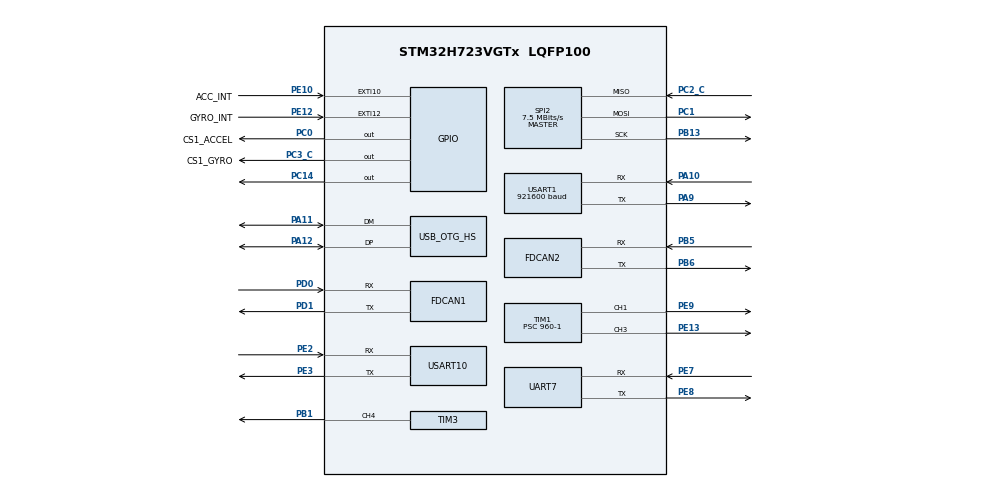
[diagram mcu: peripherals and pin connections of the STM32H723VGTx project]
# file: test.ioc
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Dma.Request0=USART1_RX
Dma.USART1_RX.0.Direction=DMA_PERIPH_TO_MEMORY
Dma.USART1_RX.0.EventEnable=DISABLE
Dma.USART1_RX.0.FIFOMode=DMA_FIFOMODE_DISABLE
Dma.USART1_RX.0.Instance=DMA1_Stream0
Dma.USART1_RX.0.MemDataAlignment=DMA_MDATAALIGN_BYTE
Dma.USART1_RX.0.MemInc=DMA_MINC_ENABLE
Dma.USART1_RX.0.Mode=DMA_NORMAL
Dma.USART1_RX.0.PeriphDataAlignment=DMA_PDATAALIGN_BYTE
Dma.USART1_RX.0.PeriphInc=DMA_PINC_DISABLE
Dma.USART1_RX.0.Polarity=HAL_DMAMUX_REQ_GEN_RISING
Dma.USART1_RX.0.Priority=DMA_PRIORITY_LOW
Dma.USART1_RX.0.RequestNumber=1
Dma.USART1_RX.0.SignalID=NONE
Dma.USART1_RX.0.SyncEnable=DISABLE
Dma.USART1_RX.0.SyncPolarity=HAL_DMAMUX_SYNC_NO_EVENT
Dma.USART1_RX.0.SyncRequestNumber=1
Dma.USART1_RX.0.SyncSignalID=NONE
FDCAN1.AutoRetransmission=DISABLE
FDCAN1.CalculateBaudRateNominal=999999
FDCAN1.CalculateTimeBitNominal=1000
FDCAN1.CalculateTimeQuantumNominal=16.666666666666668
FDCAN1.DataPrescaler=5
FDCAN1.DataSyncJumpWidth=6
FDCAN1.DataTimeSeg1=17
FDCAN1.DataTimeSeg2=6
FDCAN1.ExtFiltersNbr=4
FDCAN1.NominalPrescaler=2
FDCAN1.NominalSyncJumpWidth=15
FDCAN1.NominalTimeSeg1=44
FDCAN1.NominalTimeSeg2=15
FDCAN1.ProtocolException=DISABLE
FDCAN1.RxBuffersNbr=8
FDCAN1.RxFifo0ElmtsNbr=8
FDCAN1.RxFifo1ElmtsNbr=8
FDCAN1.StdFiltersNbr=4
FDCAN1.TxBuffersNbr=8
FDCAN1.TxEventsNbr=8
FDCAN1.TxFifoQueueElmtsNbr=8
FDCAN2.CalculateBaudRateNominal=800000
FDCAN2.CalculateTimeBitNominal=1250
FDCAN2.CalculateTimeQuantumNominal=16.666666666666668
FDCAN2.DataPrescaler=5
FDCAN2.DataSyncJumpWidth=6
FDCAN2.DataTimeSeg1=23
FDCAN2.DataTimeSeg2=6
FDCAN2.ExtFiltersNbr=4
FDCAN2.MessageRAMOffset=853
FDCAN2.NominalPrescaler=2
FDCAN2.NominalSyncJumpWidth=15
FDCAN2.NominalTimeSeg1=59
FDCAN2.NominalTimeSeg2=15
FDCAN2.ProtocolException=ENABLE
FDCAN2.RxBuffersNbr=8
FDCAN2.RxFifo0ElmtsNbr=8
FDCAN2.RxFifo1ElmtsNbr=8
FDCAN2.StdFiltersNbr=4
FDCAN2.TxBuffersNbr=8
FDCAN2.TxEventsNbr=8
FDCAN2.TxFifoQueueElmtsNbr=8
FREERTOS.Tasks01=defaultTask,24,128,StartDefaultTask,Default,NULL,Dynamic,NULL,NULL
Mcu.Family=STM32H7
Mcu.Name=STM32H723VGTx
Mcu.Package=LQFP100
NVIC.DMA1_Stream0_IRQn=true\:5\:0\:false\:false\:true\:true\:false\:true\:true
NVIC.EXTI15_10_IRQn=true\:6\:0\:true\:false\:true\:true\:true\:true\:true
NVIC.FDCAN1_IT0_IRQn=true\:6\:0\:true\:false\:true\:true\:true\:true\:true
NVIC.FDCAN1_IT1_IRQn=true\:6\:0\:true\:false\:true\:true\:true\:true\:true
NVIC.FDCAN2_IT0_IRQn=true\:5\:0\:false\:false\:true\:true\:true\:true\:true
NVIC.FDCAN2_IT1_IRQn=true\:5\:0\:false\:false\:true\:true\:true\:true\:true
NVIC.OTG_HS_IRQn=true\:5\:0\:false\:false\:true\:true\:true\:true\:true
NVIC.PriorityGroup=NVIC_PRIORITYGROUP_4
NVIC.TIM2_IRQn=true\:15\:0\:false\:false\:true\:false\:false\:true\:true
NVIC.TimeBase=TIM2_IRQn
NVIC.TimeBaseIP=TIM2
NVIC.USART1_IRQn=true\:5\:0\:false\:false\:true\:true\:true\:true\:true
PA10.Mode=Asynchronous
PA10.Signal=USART1_RX
PA11.Mode=Device_Only_FS
PA11.Signal=USB_OTG_HS_DM
PA12.Mode=Device_Only_FS
PA12.Signal=USB_OTG_HS_DP
PA13(JTMS/SWDIO).Mode=Serial_Wire
PA13(JTMS/SWDIO).Signal=DEBUG_JTMS-SWDIO
PA14(JTCK/SWCLK).Mode=Serial_Wire
PA14(JTCK/SWCLK).Signal=DEBUG_JTCK-SWCLK
PA9.Mode=Asynchronous
PA9.Signal=USART1_TX
PB1.Signal=S_TIM3_CH4
PB13.Mode=Full_Duplex_Master
PB13.Signal=SPI2_SCK
PB5.Mode=FDCAN_Activate
PB5.Signal=FDCAN2_RX
PB6.Mode=FDCAN_Activate
PB6.Signal=FDCAN2_TX
PC0.GPIO_Label=CS1_ACCEL
PC0.GPIO_Speed=GPIO_SPEED_FREQ_VERY_HIGH
PC0.PinState=GPIO_PIN_SET
PC0.Signal=GPIO_Output
PC1.Mode=Full_Duplex_Master
PC1.Signal=SPI2_MOSI
PC14-OSC32_IN.GPIO_ModeDefaultOutputPP=GPIO_MODE_OUTPUT_PP
PC14-OSC32_IN.GPIO_PuPd=GPIO_PULLUP
PC14-OSC32_IN.PinState=GPIO_PIN_SET
PC14-OSC32_IN.Signal=GPIO_Output
PC2_C.Mode=Full_Duplex_Master
PC2_C.Signal=SPI2_MISO
PC3_C.GPIO_Label=CS1_GYRO
PC3_C.GPIO_Speed=GPIO_SPEED_FREQ_VERY_HIGH
PC3_C.PinState=GPIO_PIN_SET
PC3_C.Signal=GPIO_Output
PD0.Mode=FDCAN_Activate
PD0.Signal=FDCAN1_RX
PD1.Mode=FDCAN_Activate
PD1.Signal=FDCAN1_TX
PE10.GPIO_Label=ACC_INT
PE10.Signal=GPXTI10
PE12.GPIO_Label=GYRO_INT
PE12.Signal=GPXTI12
PE13.Signal=S_TIM1_CH3
PE2.Mode=Asynchronous
PE2.Signal=USART10_RX
PE3.Mode=Asynchronous
PE3.Signal=USART10_TX
PE7.Mode=Asynchronous
PE7.Signal=UART7_RX
PE8.Mode=Asynchronous
PE8.Signal=UART7_TX
PE9.Signal=S_TIM1_CH1
PH0-OSC_IN.Mode=HSE-External-Oscillator
PH0-OSC_IN.Signal=RCC_OSC_IN
PH1-OSC_OUT.Mode=HSE-External-Oscillator
PH1-OSC_OUT.Signal=RCC_OSC_OUT
ProjectManager.HeapSize=0x200
ProjectManager.StackSize=0x400
ProjectManager.TargetToolchain=STM32CubeIDE
RCC.ADCFreq_Value=120000000
RCC.APB1Freq_Value=120000000
RCC.APB2Freq_Value=120000000
RCC.APB3Freq_Value=120000000
RCC.APB4Freq_Value=120000000
RCC.CortexFreq_Value=480000000
RCC.D1PPRE=RCC_APB3_DIV2
RCC.D2PPRE1=RCC_APB1_DIV2
RCC.D2PPRE2=RCC_APB2_DIV2
RCC.D3PPRE=RCC_APB4_DIV2
RCC.DIVM1=2
RCC.DIVM2=2
RCC.DIVN1=40
RCC.DIVN2=20
RCC.DIVP1=1
RCC.FDCANCLockSelection=RCC_FDCANCLKSOURCE_PLL2
RCC.HCLKFreq_Value=240000000
RCC.HPRE=RCC_HCLK_DIV2
RCC.HSE_VALUE=24000000
RCC.PLL2FRACN=0
RCC.PLLFRACN=0
RCC.PLLSourceVirtual=RCC_PLLSOURCE_HSE
RCC.SYSCLKFreq_VALUE=480000000
RCC.SYSCLKSource=RCC_SYSCLKSOURCE_PLLCLK
RCC.USBCLockSelection=RCC_USBCLKSOURCE_HSI48
RCC.USBFreq_Value=48000000
SH.S_TIM1_CH1.0=TIM1_CH1,PWM Generation1 CH1
SH.S_TIM1_CH3.0=TIM1_CH3,PWM Generation3 CH3
SH.S_TIM3_CH4.0=TIM3_CH4,PWM Generation4 CH4
SPI2.BaudRatePrescaler=SPI_BAUDRATEPRESCALER_32
SPI2.CLKPhase=SPI_PHASE_2EDGE
SPI2.CLKPolarity=SPI_POLARITY_HIGH
SPI2.CalculateBaudRate=7.5 MBits/s
SPI2.DataSize=SPI_DATASIZE_8BIT
SPI2.Direction=SPI_DIRECTION_2LINES
SPI2.Mode=SPI_MODE_MASTER
SPI2.VirtualType=VM_MASTER
STMicroelectronics.X-CUBE-ALGOBUILD.1.4.0.LibraryCcDSPOoLibraryJjDSPOoLibrary=true
TIM1.Channel-PWM\ Generation1\ CH1=TIM_CHANNEL_1
TIM1.Channel-PWM\ Generation3\ CH3=TIM_CHANNEL_3
TIM1.Prescaler=960-1
TIM3.AutoReloadPreload=TIM_AUTORELOAD_PRELOAD_ENABLE
TIM3.Channel-PWM\ Generation4\ CH4=TIM_CHANNEL_4
TIM3.Period=10000-1
TIM3.Prescaler=24-1
USART1.BaudRate=921600
USART1.VirtualMode-Asynchronous=VM_ASYNC
USART10.VirtualMode=VM_ASYNC
USB_DEVICE.CLASS_NAME_HS=CDC
USB_DEVICE.VirtualMode=Cdc
USB_DEVICE.VirtualModeHS=Cdc_HS
USB_OTG_HS.VirtualMode-Device_Only_FS=Device_Only_FS
VP_FREERTOS_VS_CMSIS_V2.Mode=CMSIS_V2
VP_MEMORYMAP_VS_MEMORYMAP.Mode=CurAppReg
VP_STMicroelectronics.X-CUBE-ALGOBUILD_VS_DSPOoLibraryJjLibrary_1.4.0_1.4.0.Mode=DSPOoLibraryJjLibrary
VP_SYS_VS_tim2.Mode=TIM2
VP_USB_DEVICE_VS_USB_DEVICE_CDC_HS.Mode=CDC_HS
board=custom

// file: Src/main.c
/* USER CODE BEGIN Header */
/**
  ******************************************************************************
  * @file           : main.c
  * @brief          : Main program body
  ******************************************************************************
  * @attention
  *
  * Copyright (c) 2025 STMicroelectronics.
  * All rights reserved.
  *
  * This software is licensed under terms that can be found in the LICENSE file
  * in the root directory of this software component.
  * If no LICENSE file comes with this software, it is provided AS-IS.
  *
  ******************************************************************************
  */
/* USER CODE END Header */
#include "main.h"
#include "cmsis_os.h"
#include "dma.h"
#include "fdcan.h"
#include "memorymap.h"
#include "spi.h"
#include "tim.h"
#include "usart.h"
#include "usb_device.h"
#include "gpio.h"

/* USER CODE BEGIN Includes */
#include "SEGGER_SYSVIEW.h"

/* USER CODE END Includes */

void SystemClock_Config(void);
void PeriphCommonClock_Config(void);
void MX_FREERTOS_Init(void);

int main(void)
{

  /* MCU Configuration--------------------------------------------------------*/

  /* Reset of all peripherals, Initializes the Flash interface and the Systick. */
  HAL_Init();

  /* Configure the system clock */
  SystemClock_Config();

  /* Configure the peripherals common clocks */
  PeriphCommonClock_Config();

  /* Initialize all configured peripherals */
  MX_GPIO_Init();
  MX_DMA_Init();
  MX_FDCAN1_Init();
  MX_FDCAN2_Init();
  MX_TIM1_Init();
  MX_UART7_Init();
  MX_USART1_UART_Init();
  MX_USART10_UART_Init();
  MX_SPI2_Init();
  MX_TIM3_Init();
  /* USER CODE BEGIN 2 */
  traceSTART();

  /* USER CODE END 2 */

  /* Init scheduler */
  osKernelInitialize();

  /* Call init function for freertos objects (in cmsis_os2.c) */
  MX_FREERTOS_Init();

  /* Start scheduler */
  osKernelStart();

  /* We should never get here as control is now taken by the scheduler */

  /* Infinite loop */
  while (1)
  {

  }
}

void SystemClock_Config(void)
{
  RCC_OscInitTypeDef RCC_OscInitStruct = {0};
  RCC_ClkInitTypeDef RCC_ClkInitStruct = {0};

  /** Supply configuration update enable
  */
  HAL_PWREx_ConfigSupply(PWR_LDO_SUPPLY);

  /** Configure the main internal regulator output voltage
  */
  __HAL_PWR_VOLTAGESCALING_CONFIG(PWR_REGULATOR_VOLTAGE_SCALE0);

  while(!__HAL_PWR_GET_FLAG(PWR_FLAG_VOSRDY)) {}

  /** Initializes the RCC Oscillators according to the specified parameters
  * in the RCC_OscInitTypeDef structure.
  */
  RCC_OscInitStruct.OscillatorType = RCC_OSCILLATORTYPE_HSI48|RCC_OSCILLATORTYPE_HSE;
  RCC_OscInitStruct.HSEState = RCC_HSE_ON;
  RCC_OscInitStruct.HSI48State = RCC_HSI48_ON;
  RCC_OscInitStruct.PLL.PLLState = RCC_PLL_ON;
  RCC_OscInitStruct.PLL.PLLSource = RCC_PLLSOURCE_HSE;
  RCC_OscInitStruct.PLL.PLLM = 2;
  RCC_OscInitStruct.PLL.PLLN = 40;
  RCC_OscInitStruct.PLL.PLLP = 1;
  RCC_OscInitStruct.PLL.PLLQ = 2;
  RCC_OscInitStruct.PLL.PLLR = 2;
  RCC_OscInitStruct.PLL.PLLRGE = RCC_PLL1VCIRANGE_3;
  RCC_OscInitStruct.PLL.PLLVCOSEL = RCC_PLL1VCOWIDE;
  RCC_OscInitStruct.PLL.PLLFRACN = 0;
  if (HAL_RCC_OscConfig(&RCC_OscInitStruct) != HAL_OK)
  {
    Error_Handler();
  }

  /** Initializes the CPU, AHB and APB buses clocks
  */
  RCC_ClkInitStruct.ClockType = RCC_CLOCKTYPE_HCLK|RCC_CLOCKTYPE_SYSCLK
                              |RCC_CLOCKTYPE_PCLK1|RCC_CLOCKTYPE_PCLK2
                              |RCC_CLOCKTYPE_D3PCLK1|RCC_CLOCKTYPE_D1PCLK1;
  RCC_ClkInitStruct.SYSCLKSource = RCC_SYSCLKSOURCE_PLLCLK;
  RCC_ClkInitStruct.SYSCLKDivider = RCC_SYSCLK_DIV1;
  RCC_ClkInitStruct.AHBCLKDivider = RCC_HCLK_DIV2;
  RCC_ClkInitStruct.APB3CLKDivider = RCC_APB3_DIV2;
  RCC_ClkInitStruct.APB1CLKDivider = RCC_APB1_DIV2;
  RCC_ClkInitStruct.APB2CLKDivider = RCC_APB2_DIV2;
  RCC_ClkInitStruct.APB4CLKDivider = RCC_APB4_DIV2;

  if (HAL_RCC_ClockConfig(&RCC_ClkInitStruct, FLASH_LATENCY_3) != HAL_OK)
  {
    Error_Handler();
  }
}

void PeriphCommonClock_Config(void)
{
  RCC_PeriphCLKInitTypeDef PeriphClkInitStruct = {0};

  /** Initializes the peripherals clock
  */
  PeriphClkInitStruct.PeriphClockSelection = RCC_PERIPHCLK_FDCAN;
  PeriphClkInitStruct.PLL2.PLL2M = 2;
  PeriphClkInitStruct.PLL2.PLL2N = 20;
  PeriphClkInitStruct.PLL2.PLL2P = 2;
  PeriphClkInitStruct.PLL2.PLL2Q = 2;
  PeriphClkInitStruct.PLL2.PLL2R = 2;
  PeriphClkInitStruct.PLL2.PLL2RGE = RCC_PLL2VCIRANGE_3;
  PeriphClkInitStruct.PLL2.PLL2VCOSEL = RCC_PLL2VCOWIDE;
  PeriphClkInitStruct.PLL2.PLL2FRACN = 0;
  PeriphClkInitStruct.FdcanClockSelection = RCC_FDCANCLKSOURCE_PLL2;
  if (HAL_RCCEx_PeriphCLKConfig(&PeriphClkInitStruct) != HAL_OK)
  {
    Error_Handler();
  }
}

void HAL_TIM_PeriodElapsedCallback(TIM_HandleTypeDef *htim)
{
  if (htim->Instance == TIM2)
  {
    HAL_IncTick();
  }
}

void Error_Handler(void)
{
  __disable_irq();
  while (1)
  {
  }
}

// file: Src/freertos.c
/* USER CODE BEGIN Header */
/**
  ******************************************************************************
  * File Name          : freertos.c
  * Description        : Code for freertos applications
  ******************************************************************************
  * @attention
  *
  * Copyright (c) 2025 STMicroelectronics.
  * All rights reserved.
  *
  * This software is licensed under terms that can be found in the LICENSE file
  * in the root directory of this software component.
  * If no LICENSE file comes with this software, it is provided AS-IS.
  *
  ******************************************************************************
  */
/* USER CODE END Header */

#include "FreeRTOS.h"
#include "task.h"
#include "main.h"
#include "cmsis_os.h"
#include "init.h"

/* Definitions for defaultTask */
osThreadId_t defaultTaskHandle;
const osThreadAttr_t defaultTask_attributes = {
  .name = "defaultTask",
  .stack_size = 128 * 4,
  .priority = (osPriority_t) osPriorityNormal,
};

void StartDefaultTask(void *argument);

extern void MX_USB_DEVICE_Init(void);
void MX_FREERTOS_Init(void); /* (MISRA C 2004 rule 8.1) */

void MX_FREERTOS_Init(void) {

  /* Create the thread(s) */
  /* creation of defaultTask */
  defaultTaskHandle = osThreadNew(StartDefaultTask, NULL, &defaultTask_attributes);

}

void StartDefaultTask(void *argument)
{
  /* init code for USB_DEVICE */
  MX_USB_DEVICE_Init();
  /* USER CODE BEGIN StartDefaultTask */
  Init();
  /* Infinite loop */
  for(;;)
  {
    osDelay(1);
  }
  /* USER CODE END StartDefaultTask */
}
